# psoc4200bl register map
Vendor: Cypress Semiconductor; Series: PSoC4200BL; File version: 1.0
CPU: CM0 r0p1, little endian, no MPU, no FPU, 2 interrupt priority bits
Registers are 32-bit, read-write, reset 0x0 unless marked. A register's access mark holds for its fields unless they carry their own. Offsets are from the block's base; [hi:lo] are bit positions; lines under a group give offsets from that group; {n}, {i} and the like mark numbered series.

## BLE (part 2 of 5) — Bluetooth Low Energy Subsystem
Base 0x402E0000
0x00 BLERD group — #REF!
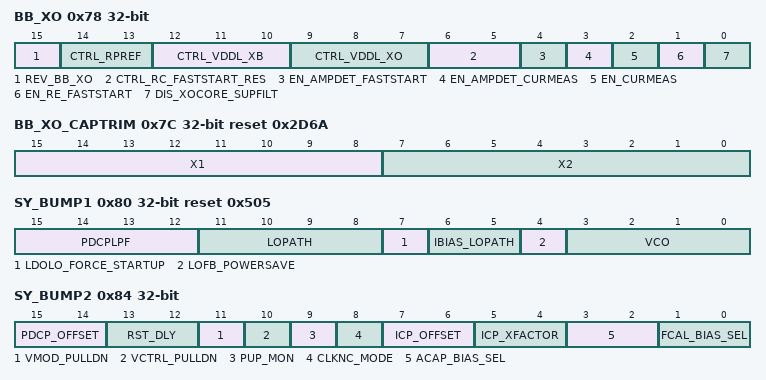
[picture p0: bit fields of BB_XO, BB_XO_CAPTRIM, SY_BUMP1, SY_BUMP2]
  0x78 BB_XO — BB bump configuration 1
    [15] REV_BB_XO
    [14:13] CTRL_RPREF — Controls the reference voltage fed as input to the regulators which generate vdd_xo and vdd_xb. 2'd0 : 1.289V 2'd1 : 1.227V 2'd2 : 1.164V 2'd3 : 1.382V
    [12:10] CTRL_VDDL_XB — Controls the value of supply filter resistance in the inverter chain. This in turn controls the supply voltage at which the inverter chain runs. 3'd0 : 1.028k 3'd1 : 1.172k 3'd2 : 1.367k 3'd3 : 1.540k 3'd4 : 1.889k 3'd5 : 2.055k 3'd6 : 0.503k 3'd7 : 0.747k
    [9:7] CTRL_VDDL_XO — Controls the value of supply filter resistance in the xo core. This in turn controls the supply voltage at which the core runs. 3'd0 : 0.769k 3'd1 : 0.877k 3'd2 : 1.023k 3'd3 : 1.152k 3'd4 : 1.413k 3'd5 : 1.537k 3'd6 : 0.376k 3'd7 : 0.559k
    [6:5] CTRL_RC_FASTSTART_RES — Controls the time constant with which the surge current from rc_faststart block decays down to zero. 2'd0 : 387us 2'd1 : 309us 2'd2 : 232us 2'd3 : 464us
    [4] EN_AMPDET_FASTSTART — This bit is used to force startup of the vtnbyr circuit in the biasgen_and_reg block of the XO. 1'd1 : startup forced 1'd0 : Normal startup
    [3] EN_AMPDET_CURMEAS — This bit can be used to disable all the caps on both X1 node and X2 node. 1'd0 : Caps Enabled 1'd1 : Caps disabled. Even when all the caps are disabled, due to finite on/off ratio of the caps, the cap on both X1 and X2 node is still 3.69pF
    [2] EN_CURMEAS — This bit is used to force startup of the positive feedback loop in the amplitude detect block of the XO. 1'd1 : startup forced 1'd0 : Normal startup
    [1] EN_RE_FASTSTART — Enables/Disables the RC faststart block in the XO. When enabled, this block provides a surge current at xo startup to reduce the settling time of the XO. 1: RC Fast start in XO is enabled 0: RC Fast start in XO is disabled
    [0] DIS_XOCORE_SUPFILT — Enables/Disables the supply filter of the XO core. 1: Disabled 0: Enabled
  0x7C BB_XO_CAPTRIM reset 0x2D6A — BB bump configuration 2
    [15:8] X1 — Bits 15-8 together control cap on X1 node. Bits 14-8 : Fine Control Value of 14-8 : Cap Value 7'd0 : 3.6900pF 7'd1 : 3.7911pF 7'd2 : 3.8922pF . . . 7'd127 : 16.4280pF Bit 15 : Coarse control 1'd0 : No additional cap turned on 1'd1 : Additional cap of 8.1pF turned on
    [7:0] X2 — Bits 7-0 together control cap on X2 node. Bits 6-0 : Fine Control Value of 6-0 : Cap Value 7'd0 : 3.6900pF 7'd1 : 3.7911pF 7'd2 : 3.8922pF . . . 7'd127 : 16.4280pF Bit 7 : Coarse control 1'd0 : No additional cap turned on 1'd1 : Additional cap of 8.1pF turned on
  0x80 SY_BUMP1 reset 0x505 — SY bump bits configuration 1
    [15:12] PDCPLPF — Bump for PD CP and LPF blocks.[2:0] is used to get range of -20 percentto +15 percent in 5 percent steps. ICP_BUMP[2:0] ICP 1 0 0 -20 percent 1 0 1 -15 percent 1 1 0 -10 percent 1 1 1 -05 percent 0 0 0 00 percent 0 0 1 05 percent 0 1 0 10 percent 0 1 1 15 percent.
    [11:8] LOPATH — Bump bits for LO path bulk bias. Goes to DIVN/FCAL/LOPATH for bumps. 2 bits for pBulk [3:2] and 2 bits for Divn/Fcal pBulk[1:0]. bump pBulk 0 0 vddx-380mV 0 1 vddx-320mV 1 0 vddx-440mV 1 1 vddx
    [7] LDOLO_FORCE_STARTUP — 1: force start-up of the VT/R circuit in VCOLOPATH LCO 0: no force start-up
    [6:5] IBIAS_LOPATH — bump bits for clkbias in lopath bump clk bias pM clk bias nM 0 0 vddo-vgsp vgsn 0 1 vddlo-vgsp-100m vgsn+100m 1 0 vddlo-vgsp-200m vgsn+200m 1 1 vddlo-vgsp-400m vgsn+400m
    [4] LOFB_POWERSAVE — 1: enable powersave for LOFB buffer 0: disable powersave for LOFB buffer This is spare bit in s8blerf_ver2 inside design
    [3:0] VCO — Bump bits for SY VCO block. Rt VCO (2 bits) - sy_bump1_vco [3:2] 00 ~ 50 Ohms 01 ~ 30 Ohms 10 ~ 22 Ohms 11 ~ 16 Ohms and Rb VCO (2 bits) - sy_bump1_vco[1:0] 00 ~ 58 Ohms 01 ~ 39 Ohms 10 ~ 22 Ohms 11 ~ 16 Ohms
  0x84 SY_BUMP2 — SY bump bits configuration 2
    [15:14] PDCP_OFFSET — Bump for the bias voltage of the 8x node. sel[1:0] R2 Vbp 00 38.5k 925mV (Default) 01 43.0k 925mV+108mV 10 31.9k 925mV-158mV 11 35.2k 925mV-080mV
    [13:12] RST_DLY — Bumping the reset (up+down) delay. Code[1:0] delay 00: 500ps 01: 424ps 10: 350ps 11: 300ps
    [11] VMOD_PULLDN — 1: Pull down control for the modulating port
    [10] VCTRL_PULLDN — 1: Test mode to pull down for noise simulation
    [9] PUP_MON — 1:Test mode to monitor buffered 1x output on the injmon buffer
    [8] CLKNC_MODE — Control the NC_clock_mux. 0: The NC clock is given from DIVN once openloop is made low. 1: The NC clock is always connected to Crystal clock
    [7:6] ICP_OFFSET — Bump bits to set the offset pulse width in RX mode Code[1:0] delay 00: 2.45ns 01: 1.75ns 10: 1.3ns 11: 25ps
    [5:4] ICP_XFACTOR — sy_bump2_icp_xfactor[1]: enable power save for SY FB buffers in TXPOWERSAVE mode, high active sy_bump2_icp_xfactor[0]: HSDIV2 is put in self oscillation mode, this can be used to find out the process corner of the chip, high active
    [3:2] ACAP_BIAS_SEL — ACAP bias voltage is selected based on these bits. Code[1:0] acapbias 00 630mV 01 700mV 10 560mV 11 595mV
    [1:0] FCAL_BIAS_SEL — VCTRL bias voltage is selected based on these bits. Code[1:0] fcal_bias 00 Vddvco/2 01 Vddvco/2 + 5.6 percent(+100mV) 10 Vddvco/2 - 2.8 percent(-050mV) 11 Vddvco/2 - 5.6 percent(-100mV)
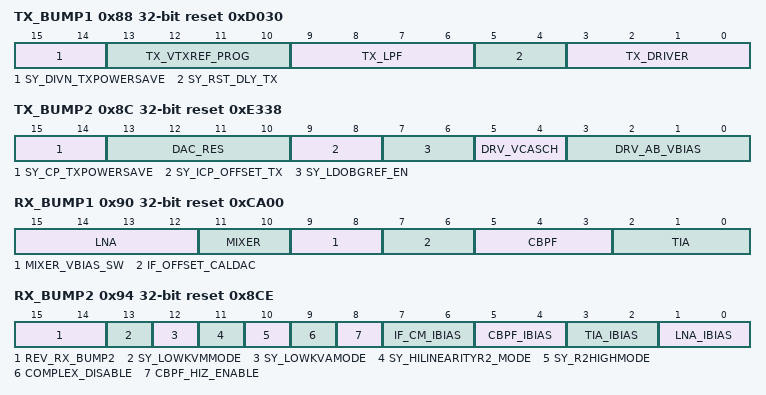
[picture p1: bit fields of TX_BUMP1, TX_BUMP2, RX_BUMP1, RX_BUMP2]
  0x88 TX_BUMP1 reset 0xD030 — transmit bump configuration 1
    [15:14] SY_DIVN_TXPOWERSAVE — Divn power save bits pup freeze txpowersave<1:0> PupBlocks 0 0 X X NONE 1 0 X X ALL 1 1 0 0 ALL 1 1 0 1 ALL-D2 1 1 1 0 ALL-D2-D1 1 1 1 1 ALL-D2-D1-Buf
    [13:10] TX_VTXREF_PROG — TX Modulation port varactor vtxref bias voltage bump settings 0000 Sets vtxref value to 100mV 0001 Sets vtxref value to 150mV 0010 Sets vtxref value to 200mV 0011 Sets vtxref value to 250mV 0100 Sets vtxref value to 300mV 0101 Sets vtxref value to 350mV 0110 Sets vtxref value to 400mV 0111 Sets vtxref value to 450mV 1000 Sets vtxref value to 500mV 1001 Sets vtxref value to 550mV 1010 Sets vtxref value to 600mV 1011 ~ 1111: unused
    [9:6] TX_LPF — Bump bits for TX LPF op-amp reference voltage [3:2] 00 Bumps the opamp ref voltage to 400mV 01 Bumps the opamp ref voltage to 450mV 10 Bumps the opamp ref voltage to 300mV 11 Bumps the opamp ref voltage to 350mVBump bits for TX LPF op-amp bias current [1:0] 00 Bumps the opamp bias current to 10u 01 Bumps the opamp bias current to 12.5u 10 Bumps the opamp bias current to 8.3u 11 Bumps the opamp bias current to 7.7u
    [5:4] SY_RST_DLY_TX — Bumping the reset (up+down) delay. Code[1:0] delay 00 500ps 01 424ps 10 350ps 11 300ps
    [3:0] TX_DRIVER — Driver bias current selection bump bit tx_bump1_tx_driver[3] Driver bias current tx_bump1_tx_driver[2] PTAT current selection Additional Class AB driver bias voltage bump related to Tx_bump2_drv_ab_vbias[3:0]
  0x8C TX_BUMP2 reset 0xE338 — transmit bump configuration 2
    [15:14] SY_CP_TXPOWERSAVE — Charge pump power save bits pup freeze txpowersave<1:0> PupBlocks 0 0 X X NONE 1 0 X X ALL 1 1 0 0 ALL 1 1 0 1 ALL-8x CP 1 1 1 0 ALL-8x-1x CP 1 1 1 1 ALL-buffer
    [13:10] DAC_RES — TX DAC load resistor bump settings 0000 DAC output resistor bump by -20 percent 0001 DAC output resistor bump by -17.5 percent 0010 DAC output resistor bump by -15 percent 0011 DAC output resistor bump by -12.5 percent 0100 DAC output resistor bump by -10 percent 0101 DAC output resistor bump by -7.5 percent 0110 DAC output resistor bump by -5 percent 0111 DAC output resistor bump by -2.5 percent 1000 DAC output resistor bump by 0 percent 1001 DAC output resistor bump by 2.5 percent 1010 DAC output resistor bump by 5 percent 1011 DAC output resistor bump by 7.5 percent 1100 DAC output resistor bump by 10 percent 1101 DAC output resistor bump by 12.5 percent 1110 DAC output resistor bump by 15 percent 1111 DAC output resistor bump by 17.5 percent
    [9:8] SY_ICP_OFFSET_TX — Bump bits to set the offset pulse width in TX mode Code[1:0] xfactor 00 : 2.45ns 01 : 1.75ns 10 : 1.3ns 11 : 25ps
    [7:6] SY_LDOBGREF_EN — Enables a bandgap (low temp coeff) for the 00 None 01 VCO ldo 10 LOPATH ldo 11 VCO+LOPATH ldo
    [5:4] DRV_VCASCH — Programs the driver cascode gate bias voltage Tx_bump2_drv_vcasch[1:0] Driver cascode bias voltage 00 Vdd_driver - 0.3V 01 Vdd_driver - 0.2V 10 Vdd_driver - 0.1V 11 Vdd_driver
    [3:0] DRV_AB_VBIAS — Bias voltage for the class-AB driver with tx_bump1_tx_driver[1:0]=00 Tx_bump2_drv_ab_vbias[3:0] Vbias_AB , mV 0000 571.224 0001 604.508 0010 626.357 0011 641.856 0100 656.04 0101 667.096 0110 678.775 0111 688.005 1000 698.817 1001 707.272 1010 718.103 1011 726.411 1100 737.995 1101 746.708 1110 759.919 1111 769.735
  0x90 RX_BUMP1 reset 0xCA00 — receiver bump configuration 1
    [15:12] LNA — rx_bump1_lna[3] 1: enables the HG and LG LNA section's cascode biases to be alive independent of whether LNA is HG or LG mode. This enables fast transition from LG to HG in AGC events rx_bump1_lna[2] 1: forces pull donwn of inputs of LNA (post AC coupling) if LNA is powered up in Hi-Z mode to ensure good isolation during DC offset calibration of Receiver chain rx_bump1_lna[1] 1: Boost the LNA bias current ot HP equivalent (1.5mA current penalty) if LNA gain is at 101 (66dB setting) and this bit is set. this boosts sensitivity by 2-3dB but the hit in the current consumption is only at 66dB gain setting. so average current comsumption in field should not be impacted much but a 2dB boost in sensitivity is seen rx_bump1_lna[0] 1: Forces the TIA to have lower feedback resistor to aviode EVM degratation in the TIA dut to complex filter distortion caused by I/Q cross talk if feedback resistors is high in the TIA
    [11:10] MIXER — bump bits to control LNA gate bias voltage in RX mode 01 0.5V 00 0.4V 11 0.3V 10 0.2V
    [9:8] MIXER_VBIAS_SW — Bump bits for Mixer VBIAS switch Mixer Bias Programmability 01 TIA CM + 0.38V 00 TIA CM + 0.3V 11 TIA CM + 0.255V 10 TIA CM + 0.17V
    [7:6] IF_OFFSET_CALDAC — Bit Setting Offset DAC LSB 00 132.4nA 01 150.8nA 10 118.0nA 11 106.5nA
    [5:3] CBPF — 3'b0xx: CBPF CM ref voltage 850mV and 1V for 1st stage and 2nd stage resp. for irefbg 8.5uA. 3'b1xx: CBPF CM ref voltage 850mV and 1V for 1st stage and 2nd stage resp. for irefbg 10uA. 3'bxx0: CBPF OTA1 CMFB tail current 17.27uA (Bias current 8.5uA). 3'bxx1: CBPF OTA1 CMFB tail current 21.58uA (Bias current 8.5uA). 3'bx0x: CBPF OTA2 CMFB tail current 17.27uA (Bias current 8.5uA). 3'bx1x: CBPF OTA2 CMFB tail current 21.58uA (Bias current 8.5uA).
    [2:0] TIA — 3'b0xx: TIA CM ref voltage 850mV for iref bias current 8.5uA. 3'b1xx: TIA CM ref voltage 850mV for iref bias current 10uA. 3'bx00: TIA OTA CMFB tail current 69uA (Bias current 8.5uA). 3'bx01: TIA OTA CMFB tail current 78uA (Bias current 8.5uA). 3'bx10: TIA OTA CMFB tail current 86uA (Bias current 8.5uA). 3'bx11: TIA OTA CMFB tail current 95uA (Bias current 8.5uA).
  0x94 RX_BUMP2 reset 0x8CE — receiver bump configuration 2
    [15:14] REV_RX_BUMP2
    [13] SY_LOWKVMMODE — Enables a lower Kv/2 mode 0 - 10 MHz/V 1 - 5 MHz/V
    [12] SY_LOWKVAMODE — Enables a lower Kv/2 mode 0 - 70 MHz/V 1 - 45 MHz/V
    [11] SY_HILINEARITYR2_MODE — Switches the RX mode between settings used in TX vs a higher linearity setting. 0 - Use same as TX 1 - Use alternative bias for RX. Effective only in RX mode. This is don't care in TX mode
    [10] SY_R2HIGHMODE — Enables a higher R2 mode for loop stabilization with low Kv and debug mode. 0 - 40 kohms 1 - 60 kohms
    [9] COMPLEX_DISABLE — setting this bit to disables the complex operation for the band pass filter configuring it as two low pass filters
    [8] CBPF_HIZ_ENABLE — Setting this bit to 1 configures the CBPF output as hi-Z enabling independent ADC testing with the injection system
    [7:6] IF_CM_IBIAS — Bump bits for Common mode setting currents of the TIA and the CBPF amplifiers (Default is 11 for current saving). 01 IBias+15 percent 00 IBias+0 percent 11 IBias-15 percent (Default) 10 IBias-20 percent
    [5:4] CBPF_IBIAS — Bump bits for BGR bias currents of Offset Calibration DAC (Default is 00) 01 IBias+15 percent 00 IBias_0 percent (Default) 11 IBias-15 percent 10 IBias-20 percent
    [3:2] TIA_IBIAS — Bump bits for RCAL bias currents of the TIA and the CBPF amplifiers (Default is 11 for current saving). 01 IBias+15 percent 00 IBias+0 percent 11 IBias-15 percent (Default) 10 IBias-20 percent
    [1:0] LNA_IBIAS — Bump bits for PTAT bias currents of LNA (Default is 00). Play with these to enable Low Power and Ultra Low Power modes in the LNA. 01 IBias+15 percent 00 IBias+0 percent (Default) 11 IBias-25 percent 10 IBias-50 percent
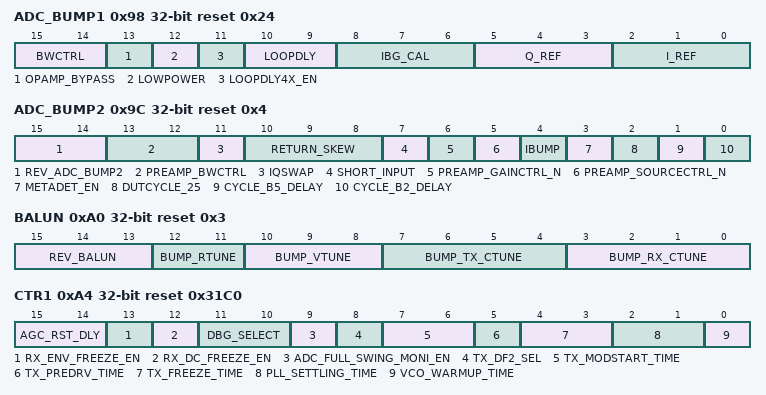
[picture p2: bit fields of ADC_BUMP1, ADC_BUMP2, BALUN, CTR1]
  0x98 ADC_BUMP1 reset 0x24 — ADC1 bump configuration
    [15:14] BWCTRL — Reference generator's bandwidth boost by injecting current in the output arm. Injection Current : 00 0 uA 01 20 uA 10 40 uA 11 60 uA
    [13] OPAMP_BYPASS — Bypass op-amp and diode connect reference generator's servo loop 0 Op-amp enabled 1 Op-amp bypassed
    [12] LOWPOWER — rCurrent reduction mode in the reference generator. 0 No bump 1 50 percent bump
    [11] LOOPDLY4X_EN — Loop delay increment by 4x in SAR return path 0 Delay determined by loopdly[1:0] 1 4x the delay dictated by the said bit
    [10:9] LOOPDLY — Loop delay control in SAR return path. 00 Min delay 11 Max delay
    [8:6] IBG_CAL — Bump bits for the preamp's bias current. X00 + 0 percent ( Ibias - 0 uA) X01 +25 percent ( Ibias - 12.5 uA) X10 - 50 percent ( Ibias - 5 uA) X11 - 25 percent ( Ibias - 7.5 uA)
    [5:3] Q_REF — Bump bits for the channel-Q reference voltage. (2's complement interpretation) Every bit changes the reference voltage by 10mV. 100 610 mV 000 650 mV 011 680 mV
    [2:0] I_REF — Bump bits for the channel-I reference voltage. (2's complement interpretation) Every bit changes the reference voltage by 10mV. See the above table
  0x9C ADC_BUMP2 reset 0x4 — ADC 2 bump configuration
    [15:14] REV_ADC_BUMP2 — [1] -- not used [0] - Enable clean Vdd for the cascodes & op-amp in refgen. The clean Vdd supplied through the diag. ( Diag code = 0101 for channel I and Diag code =1101 for channel Q). Default connection to the internal Vdd
    [13:12] PREAMP_BWCTRL — Bandwidth bump bits for the preamp. Each bit connects a 5fF cap to the output nodes. No cap is connected by default
    [11] IQSWAP — Swaps the I and Q channel Vbg/R for ref.gen 0 No swap 1 Enable swapping
    [10:8] RETURN_SKEW — Delaying the sampling clock from the comparator wrt to the data. 000 Min delay 111 Max delay
    [7] SHORT_INPUT — Put the ADC in idle channel mode. Inputs are shorted to locally generated 1V signal. 0 Normal operation 1 Idle channel mode
    [6] PREAMP_GAINCTRL_N — Enable preamp's low/high gain modes over conversion cycle. 0 Functionality enabled 1 Functionality disabled
    [5] PREAMP_SOURCECTRL_N — Disconnect source coupled node of the preamp during track phase. 0 Functionality enabled 1 Functionality disabled
    [4] IBUMP — 0: 6dB attenuation in CBPF gain only at lowest gain setting to improve the Max signal level the receiver can tolarate Note: in order to chare the tub width with AGC disabled, this back off mode is effective only with AGC profile set to rev** mode. This is in reg0xa4[3] which needs to be set to '0' for rev** profile
    [3] METADET_EN — Enable meta detection
    [2] DUTCYCLE_25 — Clock duty cycle control 0 50 percent time for track phase & 50 percent time for convert phase 1 25 percent time for track phase & 75 percent time for convert phase
    [1] CYCLE_B5_DELAY — Enable redundant conversion cycle at b5 position. 0 Disabled 1 Enabled
    [0] CYCLE_B2_DELAY — Enable redundant conversion cycle at b2 position. 0 Enabled 1 Disabled
  0xA0 BALUN reset 0x3 — BALUN bump configuration
    [15:13] REV_BALUN — resereved for feature
    [12:11] BUMP_RTUNE — resereved for feature
    [10:8] BUMP_VTUNE — resereved for feature
    [7:4] BUMP_TX_CTUNE — Programmable bits to change tuning capacitance in the Balun primary side in TX operation Balun_bump_tx_ctune[3:0] Ctune, fF 0000 42.5 0001 48.8 0010 55.1 0011 61.4 0100 67.7 0101 74 0110 80.3 0111 86.6 1000 92.9 1001 99.2 1010 105.5 1011 111.8 1100 118.1 1101 124.4 1110 130.7 1111 137
    [3:0] BUMP_RX_CTUNE — Programmable bits to change tuning capacitance in the Balun primary side in RX operation Balun_bump_tx_ctune[3:0] Ctune, fF 0000 42.5 0001 48.8 0010 55.1 0011 61.4 0100 67.7 0101 74 0110 80.3 0111 86.6 1000 92.9 1001 99.2 1010 105.5 1011 111.8 1100 118.1 1101 124.4 1110 130.7 1111 137
  0xA4 CTR1 reset 0x31C0 — RFCTRL control timing 1
    [15:14] AGC_RST_DLY — 00: 0.25us delay; 01: 1.25us delay, 10: 2.25us delay, 11: 3.25us delay
    [13] RX_ENV_FREEZE_EN — demodulation soft reset to frequency tracking enabled, high active
    [12] RX_DC_FREEZE_EN — demodulation soft reset to DC cancellation enabled, high active
    [11:10] DBG_SELECT — 00: demod soft reset / AGC reset, 01: AGC FSM MSB and f_n_rxen 10: gain decrease and gain increase. 11: ADC full swing detection and ADC saturation detected signal
    [9] ADC_FULL_SWING_MONI_EN — when ctr1_adc_full_swing_moni_en is set and ctr1_dbg_select is 2'b11. ADC full swing detection can be monitored in debug pin
    [8] TX_DF2_SEL — 0: DF2 Max frequency deviation as 224KHz 1: DF2 Max frequency deviation as 242KHz
    [7:6] TX_MODSTART_TIME — this controls the time between the PUP_TX_DRIVER going high and when f_n_txen is asserted. 00: 0us, 01: 1us, 10: 2us, 11, 3us
    [5] TX_PREDRV_TIME — PA predrive pup time, 1:powered up after LDO, 0: powered up after KVCAL
    [4:3] TX_FREEZE_TIME — tx freeze time 00: 30us, 01: 40us, 10: 50us, 11: 25us
    [2:1] PLL_SETTLING_TIME — PLL setting time 00: 25us, 01: 30us, 10: 40us, 11:50us
    [0] VCO_WARMUP_TIME — vco warm up time, 1: 10us, 0: 5us
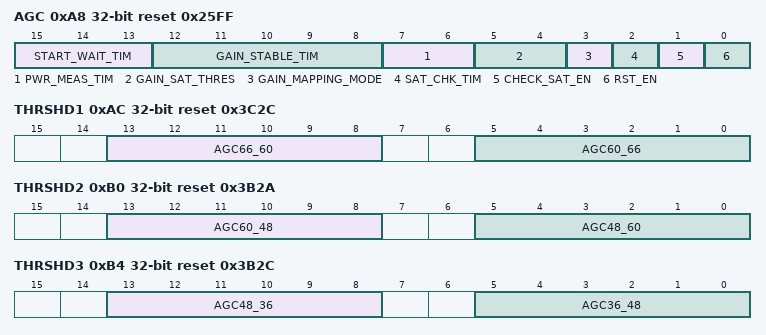
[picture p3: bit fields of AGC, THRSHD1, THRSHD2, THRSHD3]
  0xA8 AGC reset 0x25FF — AGC timing conifguration
    [15:13] START_WAIT_TIM — start AGC waiting time when RFCTRL set AGC enable 1 represents 1us, base 1us
    [12:8] GAIN_STABLE_TIM — gain stable time after gain assignment. 1 represents one 12Mhz clock
    [7:6] PWR_MEAS_TIM — AGC power measurement time 11: 1us, 10: 0.75us, 01: 0.5us, 00:0.25us
    [5:4] GAIN_SAT_THRES — ADC saturated detection threshold for doing a fast transition 00: 0dBm; 01: 1dBm; 10: 2dBm, 11: 3dBm
    [3] GAIN_MAPPING_MODE — 0: Atlantis TC rev** gaim mapping 1: Atlantis TC revA gain mapping
    [2] SAT_CHK_TIM — ADC saturated detection timing 0: 3 12MHz clock;1:3 12MHz clock;
    [1] CHECK_SAT_EN — 1: quick check saturated ADC 0: mearue ADC power at fixed period
    [0] RST_EN — 1: AGC soft reset enable
  0xAC THRSHD1 reset 0x3C2C — AGC step threshold 1
    [13:8] AGC66_60 — threshold gain changge from 60dB to 48dB
    [5:0] AGC60_66 — threshold gain changge from 66dB to60dB
  0xB0 THRSHD2 reset 0x3B2A — AGC step threshold 2
    [13:8] AGC60_48 — threshold gain changge from 48dB to 60dB
    [5:0] AGC48_60 — threshold gain changge from 60dB to48dB
  0xB4 THRSHD3 reset 0x3B2C — AGC step threshold 3
    [13:8] AGC48_36 — threshold gain changge from 366dB to 48dB
    [5:0] AGC36_48 — threshold gain changge from 48dB to 36dB
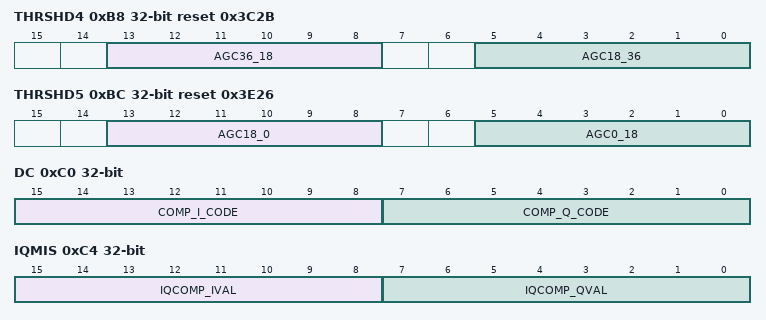
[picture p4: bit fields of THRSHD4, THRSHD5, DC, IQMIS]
  0xB8 THRSHD4 reset 0x3C2B — AGC step threshold 4
    [13:8] AGC36_18 — threshold gain changge from 18dB to 36dB
    [5:0] AGC18_36 — threshold gain changge from 36dB to 18dB
  0xBC THRSHD5 reset 0x3E26 — AGC step threshold 5
    [13:8] AGC18_0 — threshold for gain change from 0dB to 18dB
    [5:0] AGC0_18 — threshold for gain change from 18dB to 0dB
  0xC0 DC — ADC I/Q DC compensate value
    [15:8] COMP_I_CODE — this code is removed from the ADC Q output. This field can be progamrmed to remove systematci DC offset
    [7:0] COMP_Q_CODE — this code is removed from the ADC I output. This field can be progamrmed to remove systematci DC offset
  0xC4 IQMIS — IQ mismatch correction value
    [15:8] IQCOMP_IVAL — Q-component of the IQ mismatch correction
    [7:0] IQCOMP_QVAL — I-component of the IQ mismatch correction
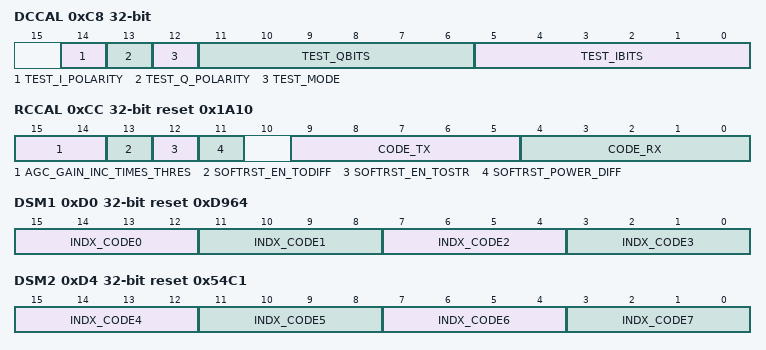
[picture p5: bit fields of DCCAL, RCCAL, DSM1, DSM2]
  0xC8 DCCAL — DC CAL and setting
    [14] TEST_I_POLARITY — 1: inverts the polarity of DCCAL I code
    [13] TEST_Q_POLARITY — 1: inverts the polarity of DCCAL Q code
    [12] TEST_MODE — enable the DCCAL test mode
    [11:6] TEST_QBITS — this value is driven to DCCAL Qcode if the DCCA: test mode enabled
    [5:0] TEST_IBITS — this value is driven to DCCAL Icode if the DCCA: test mode enabled
  0xCC RCCAL reset 0x1A10 — TX LPF and TIA/CBPF RC code
    [15:14] AGC_GAIN_INC_TIMES_THRES — AGC gain increase requirement wait times: 00: respose for 1st gain increase request 01: respone for 2nd gain increase request 10: respons for 3rd gain increase request 11: respons for 4th gain increase request
    [13] SOFTRST_EN_TODIFF — soft reset is enable to diffdet block
    [12] SOFTRST_EN_TOSTR — soft reset is enabled to STR block
    [11] SOFTRST_POWER_DIFF — soft reset power change detection, 1: 12dB, 0:6dB
    [9:5] CODE_TX — force RC code for TX LPF under test mode
    [4:0] CODE_RX — force RC code for TIA/CBPF under test mode
  0xD0 DSM1 reset 0xD964 — DSM freeze code 1
    [15:12] INDX_CODE0 — index at which DSM code should be freezed when fection value = 0
    [11:8] INDX_CODE1 — index at which DSM code should be freezed when fection value = 1/24
    [7:4] INDX_CODE2 — index at which DSM code should be freezed when fection value = 2/24
    [3:0] INDX_CODE3 — index at which DSM code should be freezed when fection value = 3/24
  0xD4 DSM2 reset 0x54C1 — DSM freeze code 2
    [31-4n:28-4n] INDX_CODE{n} (n=4..7) — index at which DSM code should be freezed when fection value = {n}/24
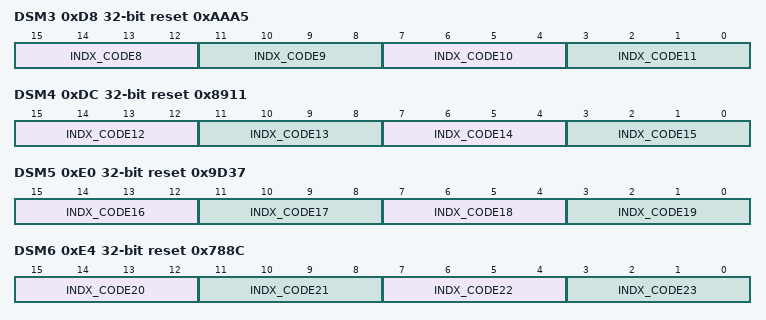
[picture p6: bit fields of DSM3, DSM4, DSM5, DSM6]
  0xD8 DSM3 reset 0xAAA5 — DSM freeze code 3
    [47-4n:44-4n] INDX_CODE{n} (n=8..11) — index at which DSM code should be freezed when fection value = {n}/24
  0xDC DSM4 reset 0x8911 — DSM freeze code 4
    [63-4n:60-4n] INDX_CODE{n} (n=12..15) — index at which DSM code should be freezed when fection value = {n}/24
  0xE0 DSM5 reset 0x9D37 — DSM freeze code 5
    [79-4n:76-4n] INDX_CODE{n} (n=16..19) — index at which DSM code should be freezed when fection value = {n}/24
  0xE4 DSM6 reset 0x788C — DSM freeze code 6
    [95-4n:92-4n] INDX_CODE{n} (n=20..23) — index at which DSM code should be freezed when fection value = {n}/24
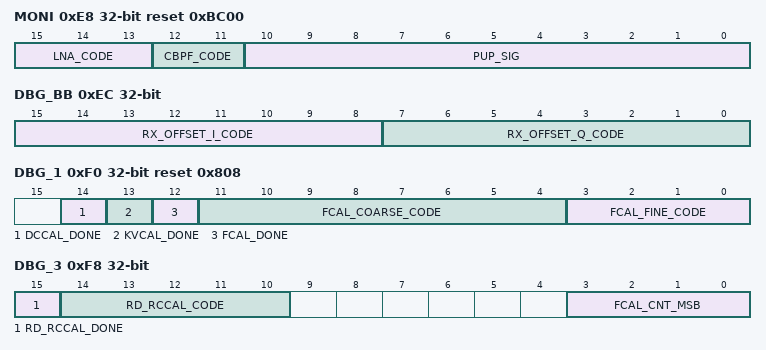
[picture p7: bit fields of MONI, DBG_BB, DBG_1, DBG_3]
  0xE8 MONI ro reset 0xBC00 — agc gain and pup signal monitor
    [15:13] LNA_CODE — lna gain code read back
    [12:11] CBPF_CODE — cbpf gain code read back
    [10:0] PUP_SIG — block pup up signals monitor. 10: iso_eanble 9: balum LDO power up, high active 8: SY bias power up, high active 7. SY VCO pup up, high active 6: TX bias pup up, high active 5. TX DAC pup up, high active 4: TX LPF pup up, high active 3. TX driver pup up, high active 2: RX LNA pup up, high active 1. RX CBPF pup up, high active 0: RX ADC ICORE pup, high active
  0xEC DBG_BB ro — RX offcal and RC cal code
    [15:8] RX_OFFSET_I_CODE — when modem_read_dc_offset_sel = 1, RX DCCAL I path can be read through this field. When modem_read_dc_offset_sel = 0, RC DC offset capture I code can be read through this field rx offsetcal Q code can be read through this field if modem_read_dc_offset_sel = 0
    [7:0] RX_OFFSET_Q_CODE — when modem_read_dc_offset_sel = 1, RX DCCAL Q path can be read through this field. When modem_read_dc_offset_sel = 0, RC DC offset capture Q code can be read through this field rx offsetcal Q code can be read through this field if modem_read_dc_offset_sel = 0
  0xF0 DBG_1 ro reset 0x808 — FCAL coarse / fine code is reflected in this field
    [14] DCCAL_DONE — 1: indicates RX DC calibration is done for current packet
    [13] KVCAL_DONE — 1: indicates TX KV calibration is done for current packet
    [12] FCAL_DONE — 1: indicates when frequency calibration is done
    [11:4] FCAL_COARSE_CODE — The FCAL coars code is reflected in this field
    [3:0] FCAL_FINE_CODE — The FCAL fine code is reflected in this field
  0xF4 DBG_2 ro — FCAL countere value ate the end of 7th bit (MSB)
    [15:0] FCAL_CNT_LSB — the dbg_fcal_cnt_sel value, the 16 LSB bits of the corresponding debug counter is pouplated in this register [6:0] is kvcal_gain when select kvcal_gain
  0xF8 DBG_3 ro — VCO OL count read out (MSB)
    [15] RD_RCCAL_DONE — RCCAL done indictor
    [14:10] RD_RCCAL_CODE — RCCAL code read out through register
    [3:0] FCAL_CNT_MSB — the dbg_fcal_cnt_sel value, the 4 MSB bits of the corresponding debug counter is pouplated in this register
  0x100 READ_IQ_1 ro — I&Q Path ADC Data
    [31:0] ADC_1 — read out I&Q path ADC data, first 16bits of I and Qcombination of 63bits
  0x104 READ_IQ_2 ro — I&Q Path ADC Data
    [31:0] ADC_2 — read out I&Q path ADC data, second 16bits of I and Qcombination of 63bits
  0x108 READ_IQ_3 ro — I&Q Path ADC Data
    [31:0] ADC_3 — read out I&Q path ADC data, third 16bits of I and Qcombination of 63bits
  0x10C READ_IQ_4 ro — I&Q Path ADC Data
    [31:0] ADC_4 — read out I&Q path ADC data, fourth 15bits of I and Qcombination of 63bits
